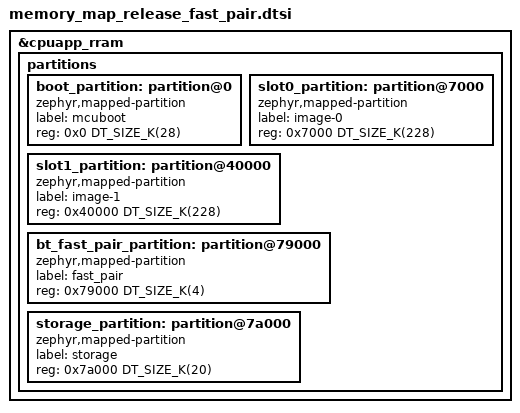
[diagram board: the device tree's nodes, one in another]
/*
 * Copyright (c) 2026 Nordic Semiconductor ASA
 *
 * SPDX-License-Identifier: LicenseRef-Nordic-5-Clause
 */

&cpuapp_rram {
	/delete-node/ partitions;

	partitions {
		#address-cells = <1>;
		#size-cells = <1>;
		ranges;

		boot_partition: partition@0 {
			compatible = "zephyr,mapped-partition";
			label = "mcuboot";
			reg = <0x0 DT_SIZE_K(28)>;
		};

		slot0_partition: partition@7000 {
			compatible = "zephyr,mapped-partition";
			label = "image-0";
			reg = <0x7000 DT_SIZE_K(228)>;
		};

		slot1_partition: partition@40000 {
			compatible = "zephyr,mapped-partition";
			label = "image-1";
			reg = <0x40000 DT_SIZE_K(228)>;
		};

		bt_fast_pair_partition: partition@79000 {
			compatible = "zephyr,mapped-partition";
			label = "fast_pair";
			reg = <0x79000 DT_SIZE_K(4)>;
		};

		storage_partition: partition@7a000 {
			compatible = "zephyr,mapped-partition";
			label = "storage";
			reg = <0x7a000 DT_SIZE_K(20)>;
		};
	};
};
